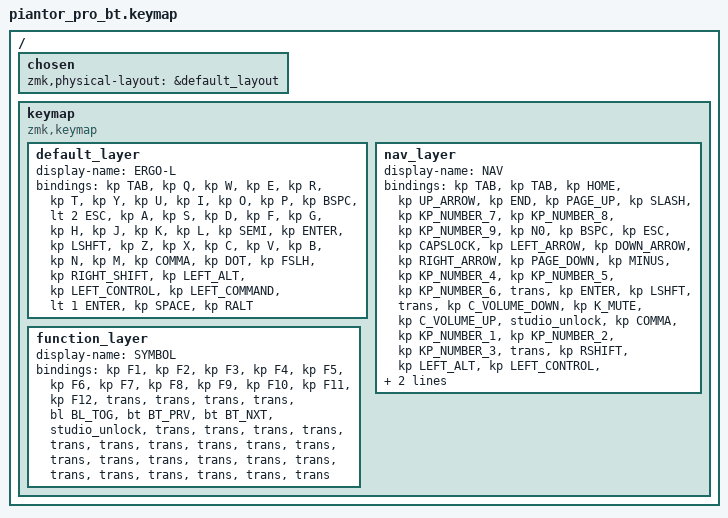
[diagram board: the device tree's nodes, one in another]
/*
 * Copyright (c) 2020 The ZMK Contributors
 *
 * SPDX-License-Identifier: MIT
 */

#include <behaviors.dtsi>
#include <dt-bindings/zmk/backlight.h>
#include <dt-bindings/zmk/bt.h>
#include <dt-bindings/zmk/keys.h>

/ {
    chosen { zmk,physical-layout = &default_layout; };
};

/ {
    keymap {
        compatible = "zmk,keymap";

        default_layer {
            display-name = "ERGO-L";

            // --------------------------------------------------------------------------------
            // |  TAB |  Q  |  W  |  E  |  R  |  T  |  Y  |  U   |  I  |  O  |  P  | BSPC |
            // | CTRL |  A  |  S  |  D  |  F  |  G  |  H  |  J   |  K  |  L  |  ;  |  '   |
            // | SHFT |  Z  |  X  |  C  |  V  |  B  |  N  |  M   |  ,  |  .  |  /  | ESC  |
            //                    | GUI | LWR | SPC | ENT | RSE  | ALT |

            bindings = <
&kp TAB  &kp Q  &kp W  &kp E  &kp R  &kp T  &kp Y  &kp U  &kp I  &kp O  &kp P  &kp BSPC  &lt 2 ESC  &kp A  &kp S  &kp D  &kp F  &kp G  &kp H  &kp J  &kp K  &kp L  &kp SEMI  &kp ENTER  &kp LSHFT  &kp Z  &kp X  &kp C  &kp V  &kp B  &kp N  &kp M  &kp COMMA  &kp DOT  &kp FSLH  &kp RIGHT_SHIFT  &kp LEFT_ALT  &kp LEFT_CONTROL  &kp LEFT_COMMAND  &lt 1 ENTER  &kp SPACE  &kp RALT
            >;
        };

        nav_layer {
            display-name = "NAV";

            // -----------------------------------------------------------------------------------------
            // |  TAB |  1  |  2  |  3  |  4  |  5    |  6  |  7  |  8  |  9  |  0  | BSPC |
            // | CTRL | BT1 | BT2 | BT3 | BT4 | BT5   | LFT | DWN |  UP | RGT |     |      |
            // | SHFT | BTCR| RGB | RST | BOOT| Unlock|     |     |     |     |     |      |
            //                    | GUI |     | SPC   | ENT |     | ALT |

            bindings = <
&kp TAB  &kp TAB  &kp HOME  &kp UP_ARROW  &kp END  &kp PAGE_UP  &kp SLASH  &kp KP_NUMBER_7  &kp KP_NUMBER_8  &kp KP_NUMBER_9  &kp N0  &kp BSPC  &kp ESC  &kp CAPSLOCK  &kp LEFT_ARROW  &kp DOWN_ARROW  &kp RIGHT_ARROW  &kp PAGE_DOWN  &kp MINUS  &kp KP_NUMBER_4  &kp KP_NUMBER_5  &kp KP_NUMBER_6  &trans  &kp ENTER  &kp LSHFT  &trans  &kp C_VOLUME_DOWN  &kp K_MUTE  &kp C_VOLUME_UP  &studio_unlock  &kp COMMA  &kp KP_NUMBER_1  &kp KP_NUMBER_2  &kp KP_NUMBER_3  &trans  &kp RSHIFT  &kp LEFT_ALT  &kp LEFT_CONTROL  &kp LEFT_COMMAND  &kp LGUI  &kp SPACE  &kp RIGHT_ALT
            >;
        };

        function_layer {
            display-name = "SYMBOL";

            // -----------------------------------------------------------------------------------------
            // |  TAB |  !  |  @  |  #  |  $  |  %  |  ^  |  &  |  *  |  (  |  )  | BSPC |
            // | CTRL |     |     |     |     |     |  -  |  =  |  [  |  ]  |  \  |  `   |
            // | SHFT |     |     |     |     |     |  _  |  +  |  {  |  }  | "|" |  ~   |
            //                    | GUI |     | SPC | ENT |     | ALT |

            bindings = <
&kp F1  &kp F2  &kp F3  &kp F4  &kp F5  &kp F6  &kp F7  &kp F8  &kp F9  &kp F10  &kp F11  &kp F12  &trans  &trans  &trans  &trans  &bl BL_TOG  &bt BT_PRV  &bt BT_NXT  &studio_unlock  &trans  &trans  &trans  &trans  &trans  &trans  &trans  &trans  &trans  &trans  &trans  &trans  &trans  &trans  &trans  &trans  &trans  &trans  &trans  &trans  &trans  &trans
            >;
        };
    };
};
